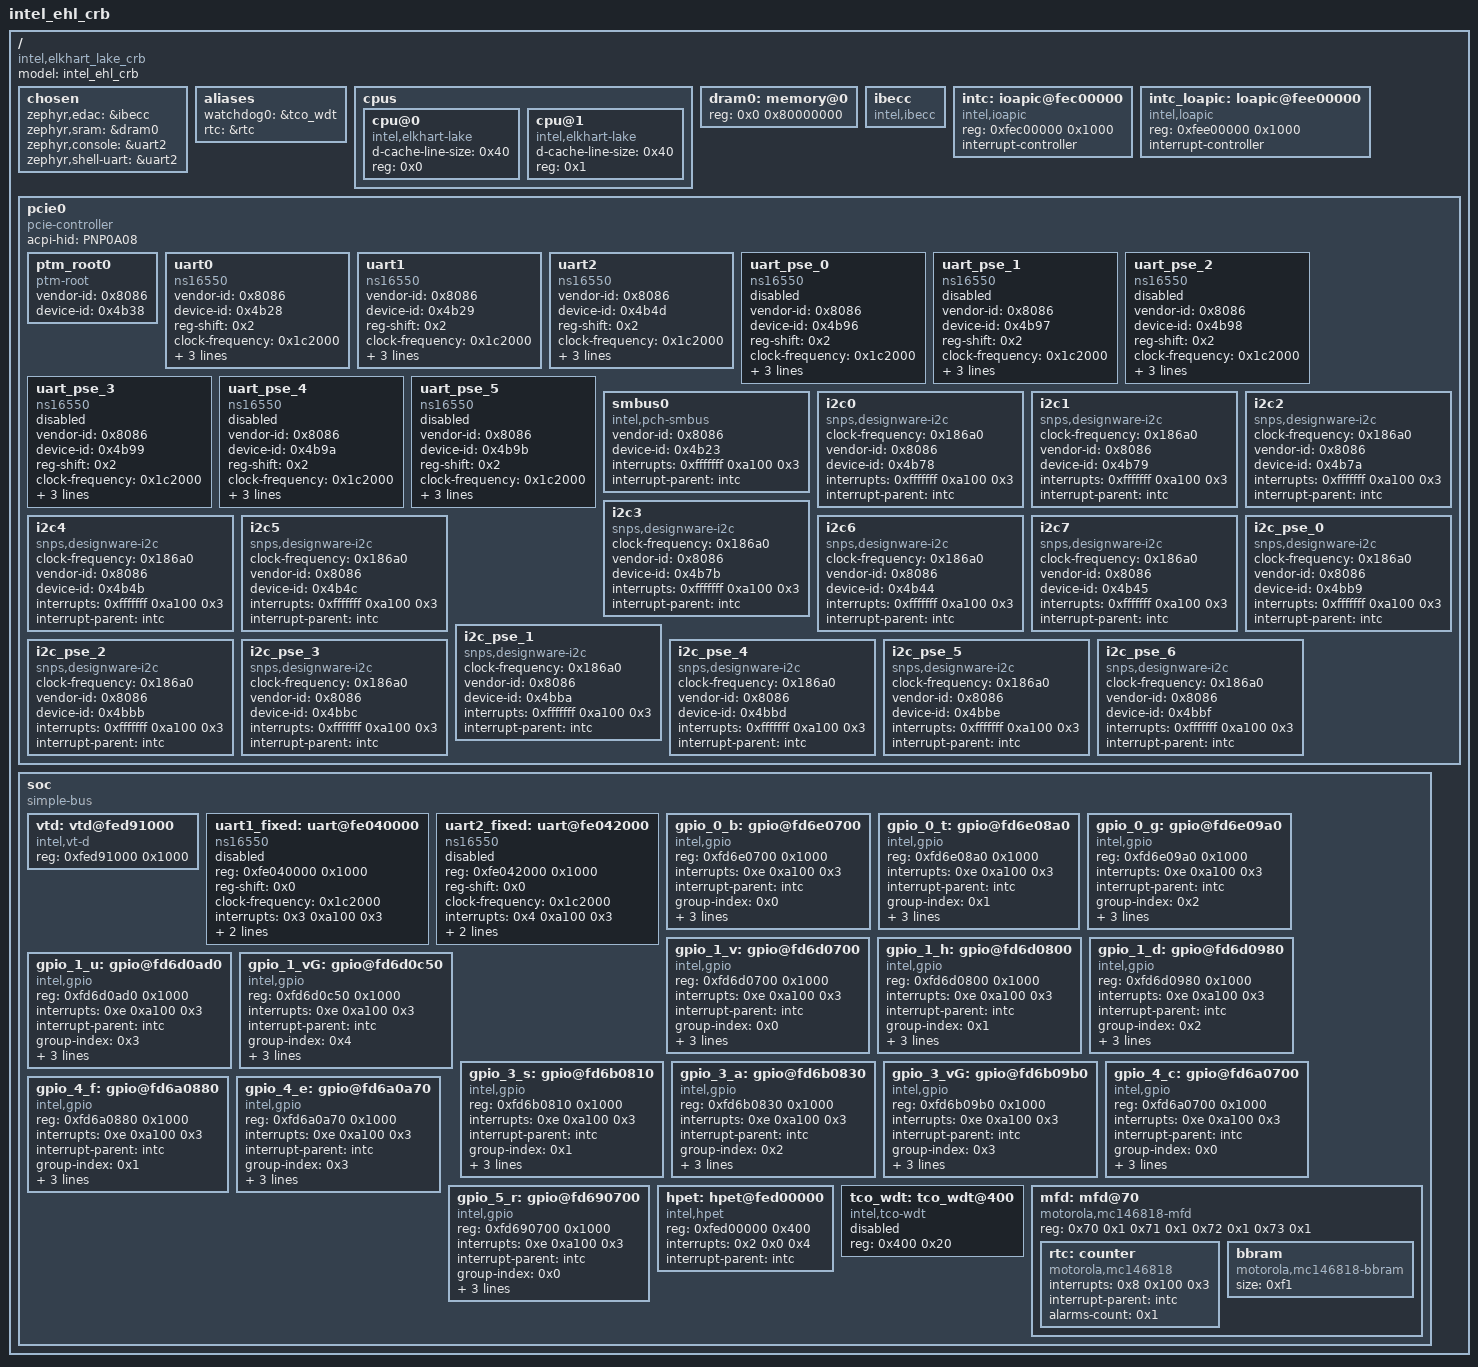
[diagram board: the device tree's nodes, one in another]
/dts-v1/;

/* node '/' defined in zephyr/dts/common/skeleton.dtsi:9 */
/ {
	#address-cells = < 0x1 >;              /* in zephyr/dts/common/skeleton.dtsi:10 */
	#size-cells = < 0x1 >;                 /* in zephyr/dts/common/skeleton.dtsi:11 */
	model = "intel_ehl_crb";               /* in zephyr/boards/intel/ehl/intel_ehl_crb.dts:16 */
	compatible = "intel,elkhart_lake_crb"; /* in zephyr/boards/intel/ehl/intel_ehl_crb.dts:17 */

	/* node '/chosen' defined in zephyr/dts/common/skeleton.dtsi:13 */
	chosen {
		zephyr,edac = &ibecc;       /* in zephyr/dts/x86/intel/elkhart_lake.dtsi:33 */
		zephyr,sram = &dram0;       /* in zephyr/boards/intel/ehl/intel_ehl_crb.dts:20 */
		zephyr,console = &uart2;    /* in zephyr/boards/intel/ehl/intel_ehl_crb.dts:21 */
		zephyr,shell-uart = &uart2; /* in zephyr/boards/intel/ehl/intel_ehl_crb.dts:22 */
	};

	/* node '/aliases' defined in zephyr/dts/common/skeleton.dtsi:15 */
	aliases {
		watchdog0 = &tco_wdt; /* in zephyr/boards/intel/ehl/intel_ehl_crb.dts:26 */
		rtc = &rtc;           /* in zephyr/boards/intel/ehl/intel_ehl_crb.dts:27 */
	};

	/* node '/cpus' defined in zephyr/dts/x86/intel/elkhart_lake.dtsi:13 */
	cpus {
		#address-cells = < 0x1 >; /* in zephyr/dts/x86/intel/elkhart_lake.dtsi:14 */
		#size-cells = < 0x0 >;    /* in zephyr/dts/x86/intel/elkhart_lake.dtsi:15 */

		/* node '/cpus/cpu@0' defined in zephyr/dts/x86/intel/elkhart_lake.dtsi:17 */
		cpu@0 {
			device_type = "cpu";               /* in zephyr/dts/x86/intel/elkhart_lake.dtsi:18 */
			compatible = "intel,elkhart-lake",
			             "intel,x86_64";       /* in zephyr/dts/x86/intel/elkhart_lake.dtsi:19 */
			d-cache-line-size = < 0x40 >;      /* in zephyr/dts/x86/intel/elkhart_lake.dtsi:20 */
			reg = < 0x0 >;                     /* in zephyr/dts/x86/intel/elkhart_lake.dtsi:21 */
		};

		/* node '/cpus/cpu@1' defined in zephyr/dts/x86/intel/elkhart_lake.dtsi:24 */
		cpu@1 {
			device_type = "cpu";               /* in zephyr/dts/x86/intel/elkhart_lake.dtsi:25 */
			compatible = "intel,elkhart-lake",
			             "intel,x86_64";       /* in zephyr/dts/x86/intel/elkhart_lake.dtsi:26 */
			d-cache-line-size = < 0x40 >;      /* in zephyr/dts/x86/intel/elkhart_lake.dtsi:27 */
			reg = < 0x1 >;                     /* in zephyr/dts/x86/intel/elkhart_lake.dtsi:28 */
		};
	};

	/* node '/memory@0' defined in zephyr/dts/x86/intel/elkhart_lake.dtsi:36 */
	dram0: memory@0 {
		device_type = "memory";   /* in zephyr/dts/x86/intel/elkhart_lake.dtsi:37 */
		reg = < 0x0 0x80000000 >; /* in zephyr/dts/x86/intel/elkhart_lake.dtsi:38 */
	};

	/* node '/ibecc' defined in zephyr/dts/x86/intel/elkhart_lake.dtsi:41 */
	ibecc: ibecc {
		compatible = "intel,ibecc"; /* in zephyr/dts/x86/intel/elkhart_lake.dtsi:42 */
		status = "okay";            /* in zephyr/dts/x86/intel/elkhart_lake.dtsi:43 */
	};

	/* node '/ioapic@fec00000' defined in zephyr/dts/x86/intel/elkhart_lake.dtsi:46 */
	intc: ioapic@fec00000 {
		compatible = "intel,ioapic"; /* in zephyr/dts/x86/intel/elkhart_lake.dtsi:47 */
		#address-cells = < 0x1 >;    /* in zephyr/dts/x86/intel/elkhart_lake.dtsi:48 */
		#interrupt-cells = < 0x3 >;  /* in zephyr/dts/x86/intel/elkhart_lake.dtsi:49 */
		reg = < 0xfec00000 0x1000 >; /* in zephyr/dts/x86/intel/elkhart_lake.dtsi:50 */
		interrupt-controller;        /* in zephyr/dts/x86/intel/elkhart_lake.dtsi:51 */
		phandle = < 0x1 >;           /* in zephyr/dts/x86/intel/elkhart_lake.dtsi:87 */
	};

	/* node '/loapic@fee00000' defined in zephyr/dts/x86/intel/elkhart_lake.dtsi:54 */
	intc_loapic: loapic@fee00000 {
		compatible = "intel,loapic"; /* in zephyr/dts/x86/intel/elkhart_lake.dtsi:55 */
		reg = < 0xfee00000 0x1000 >; /* in zephyr/dts/x86/intel/elkhart_lake.dtsi:56 */
		interrupt-controller;        /* in zephyr/dts/x86/intel/elkhart_lake.dtsi:57 */
		#interrupt-cells = < 0x3 >;  /* in zephyr/dts/x86/intel/elkhart_lake.dtsi:58 */
		#address-cells = < 0x1 >;    /* in zephyr/dts/x86/intel/elkhart_lake.dtsi:59 */
	};

	/* node '/pcie0' defined in zephyr/dts/x86/intel/elkhart_lake.dtsi:62 */
	pcie0: pcie0 {
		#address-cells = < 0x1 >;       /* in zephyr/dts/x86/intel/elkhart_lake.dtsi:63 */
		#size-cells = < 0x1 >;          /* in zephyr/dts/x86/intel/elkhart_lake.dtsi:64 */
		compatible = "pcie-controller"; /* in zephyr/dts/x86/intel/elkhart_lake.dtsi:65 */
		acpi-hid = "PNP0A08";           /* in zephyr/dts/x86/intel/elkhart_lake.dtsi:66 */
		ranges;                         /* in zephyr/dts/x86/intel/elkhart_lake.dtsi:67 */

		/* node '/pcie0/ptm_root0' defined in zephyr/dts/x86/intel/elkhart_lake.dtsi:69 */
		ptm_root0: ptm_root0 {
			compatible = "ptm-root"; /* in zephyr/dts/x86/intel/elkhart_lake.dtsi:70 */
			vendor-id = < 0x8086 >;  /* in zephyr/dts/x86/intel/elkhart_lake.dtsi:72 */
			device-id = < 0x4b38 >;  /* in zephyr/dts/x86/intel/elkhart_lake.dtsi:73 */
			status = "okay";         /* in zephyr/dts/x86/intel/elkhart_lake.dtsi:75 */
		};

		/* node '/pcie0/uart0' defined in zephyr/dts/x86/intel/elkhart_lake.dtsi:78 */
		uart0: uart0 {
			compatible = "ns16550";                /* in zephyr/dts/x86/intel/elkhart_lake.dtsi:79 */
			vendor-id = < 0x8086 >;                /* in zephyr/dts/x86/intel/elkhart_lake.dtsi:81 */
			device-id = < 0x4b28 >;                /* in zephyr/dts/x86/intel/elkhart_lake.dtsi:82 */
			reg-shift = < 0x2 >;                   /* in zephyr/dts/x86/intel/elkhart_lake.dtsi:84 */
			clock-frequency = < 0x1c2000 >;        /* in zephyr/dts/x86/intel/elkhart_lake.dtsi:85 */
			interrupts = < 0xfffffff 0xa100 0x3 >; /* in zephyr/dts/x86/intel/elkhart_lake.dtsi:86 */
			interrupt-parent = < &intc >;          /* in zephyr/dts/x86/intel/elkhart_lake.dtsi:87 */
			status = "okay";                       /* in zephyr/dts/x86/intel/elkhart_lake.dtsi:88 */
			current-speed = < 0x1c200 >;           /* in zephyr/dts/x86/intel/elkhart_lake.dtsi:89 */
		};

		/* node '/pcie0/uart1' defined in zephyr/dts/x86/intel/elkhart_lake.dtsi:92 */
		uart1: uart1 {
			compatible = "ns16550";                /* in zephyr/dts/x86/intel/elkhart_lake.dtsi:93 */
			vendor-id = < 0x8086 >;                /* in zephyr/dts/x86/intel/elkhart_lake.dtsi:95 */
			device-id = < 0x4b29 >;                /* in zephyr/dts/x86/intel/elkhart_lake.dtsi:96 */
			reg-shift = < 0x2 >;                   /* in zephyr/dts/x86/intel/elkhart_lake.dtsi:98 */
			clock-frequency = < 0x1c2000 >;        /* in zephyr/dts/x86/intel/elkhart_lake.dtsi:99 */
			interrupts = < 0xfffffff 0xa100 0x3 >; /* in zephyr/dts/x86/intel/elkhart_lake.dtsi:100 */
			interrupt-parent = < &intc >;          /* in zephyr/dts/x86/intel/elkhart_lake.dtsi:101 */
			status = "okay";                       /* in zephyr/dts/x86/intel/elkhart_lake.dtsi:103 */
			current-speed = < 0x1c200 >;           /* in zephyr/dts/x86/intel/elkhart_lake.dtsi:104 */
		};

		/* node '/pcie0/uart2' defined in zephyr/dts/x86/intel/elkhart_lake.dtsi:107 */
		uart2: uart2 {
			compatible = "ns16550";                /* in zephyr/dts/x86/intel/elkhart_lake.dtsi:108 */
			vendor-id = < 0x8086 >;                /* in zephyr/dts/x86/intel/elkhart_lake.dtsi:110 */
			device-id = < 0x4b4d >;                /* in zephyr/dts/x86/intel/elkhart_lake.dtsi:111 */
			reg-shift = < 0x2 >;                   /* in zephyr/dts/x86/intel/elkhart_lake.dtsi:113 */
			clock-frequency = < 0x1c2000 >;        /* in zephyr/dts/x86/intel/elkhart_lake.dtsi:114 */
			interrupts = < 0xfffffff 0xa100 0x3 >; /* in zephyr/dts/x86/intel/elkhart_lake.dtsi:115 */
			interrupt-parent = < &intc >;          /* in zephyr/dts/x86/intel/elkhart_lake.dtsi:116 */
			status = "okay";                       /* in zephyr/dts/x86/intel/elkhart_lake.dtsi:118 */
			current-speed = < 0x1c200 >;           /* in zephyr/dts/x86/intel/elkhart_lake.dtsi:119 */
		};

		/* node '/pcie0/uart_pse_0' defined in zephyr/dts/x86/intel/elkhart_lake.dtsi:122 */
		uart_pse_0: uart_pse_0 {
			compatible = "ns16550";                /* in zephyr/dts/x86/intel/elkhart_lake.dtsi:123 */
			vendor-id = < 0x8086 >;                /* in zephyr/dts/x86/intel/elkhart_lake.dtsi:125 */
			device-id = < 0x4b96 >;                /* in zephyr/dts/x86/intel/elkhart_lake.dtsi:126 */
			reg-shift = < 0x2 >;                   /* in zephyr/dts/x86/intel/elkhart_lake.dtsi:128 */
			clock-frequency = < 0x1c2000 >;        /* in zephyr/dts/x86/intel/elkhart_lake.dtsi:129 */
			interrupts = < 0xfffffff 0xa100 0x3 >; /* in zephyr/dts/x86/intel/elkhart_lake.dtsi:130 */
			interrupt-parent = < &intc >;          /* in zephyr/dts/x86/intel/elkhart_lake.dtsi:131 */
			status = "disabled";                   /* in zephyr/dts/x86/intel/elkhart_lake.dtsi:133 */
			current-speed = < 0x1c200 >;           /* in zephyr/dts/x86/intel/elkhart_lake.dtsi:134 */
		};

		/* node '/pcie0/uart_pse_1' defined in zephyr/dts/x86/intel/elkhart_lake.dtsi:137 */
		uart_pse_1: uart_pse_1 {
			compatible = "ns16550";                /* in zephyr/dts/x86/intel/elkhart_lake.dtsi:138 */
			vendor-id = < 0x8086 >;                /* in zephyr/dts/x86/intel/elkhart_lake.dtsi:140 */
			device-id = < 0x4b97 >;                /* in zephyr/dts/x86/intel/elkhart_lake.dtsi:141 */
			reg-shift = < 0x2 >;                   /* in zephyr/dts/x86/intel/elkhart_lake.dtsi:143 */
			clock-frequency = < 0x1c2000 >;        /* in zephyr/dts/x86/intel/elkhart_lake.dtsi:144 */
			interrupts = < 0xfffffff 0xa100 0x3 >; /* in zephyr/dts/x86/intel/elkhart_lake.dtsi:145 */
			interrupt-parent = < &intc >;          /* in zephyr/dts/x86/intel/elkhart_lake.dtsi:146 */
			status = "disabled";                   /* in zephyr/dts/x86/intel/elkhart_lake.dtsi:148 */
			current-speed = < 0x1c200 >;           /* in zephyr/dts/x86/intel/elkhart_lake.dtsi:149 */
		};

		/* node '/pcie0/uart_pse_2' defined in zephyr/dts/x86/intel/elkhart_lake.dtsi:152 */
		uart_pse_2: uart_pse_2 {
			compatible = "ns16550";                /* in zephyr/dts/x86/intel/elkhart_lake.dtsi:153 */
			vendor-id = < 0x8086 >;                /* in zephyr/dts/x86/intel/elkhart_lake.dtsi:155 */
			device-id = < 0x4b98 >;                /* in zephyr/dts/x86/intel/elkhart_lake.dtsi:156 */
			reg-shift = < 0x2 >;                   /* in zephyr/dts/x86/intel/elkhart_lake.dtsi:158 */
			clock-frequency = < 0x1c2000 >;        /* in zephyr/dts/x86/intel/elkhart_lake.dtsi:159 */
			interrupts = < 0xfffffff 0xa100 0x3 >; /* in zephyr/dts/x86/intel/elkhart_lake.dtsi:160 */
			interrupt-parent = < &intc >;          /* in zephyr/dts/x86/intel/elkhart_lake.dtsi:161 */
			status = "disabled";                   /* in zephyr/dts/x86/intel/elkhart_lake.dtsi:163 */
			current-speed = < 0x1c200 >;           /* in zephyr/dts/x86/intel/elkhart_lake.dtsi:164 */
		};

		/* node '/pcie0/uart_pse_3' defined in zephyr/dts/x86/intel/elkhart_lake.dtsi:167 */
		uart_pse_3: uart_pse_3 {
			compatible = "ns16550";                /* in zephyr/dts/x86/intel/elkhart_lake.dtsi:168 */
			vendor-id = < 0x8086 >;                /* in zephyr/dts/x86/intel/elkhart_lake.dtsi:170 */
			device-id = < 0x4b99 >;                /* in zephyr/dts/x86/intel/elkhart_lake.dtsi:171 */
			reg-shift = < 0x2 >;                   /* in zephyr/dts/x86/intel/elkhart_lake.dtsi:173 */
			clock-frequency = < 0x1c2000 >;        /* in zephyr/dts/x86/intel/elkhart_lake.dtsi:174 */
			interrupts = < 0xfffffff 0xa100 0x3 >; /* in zephyr/dts/x86/intel/elkhart_lake.dtsi:175 */
			interrupt-parent = < &intc >;          /* in zephyr/dts/x86/intel/elkhart_lake.dtsi:176 */
			status = "disabled";                   /* in zephyr/dts/x86/intel/elkhart_lake.dtsi:178 */
			current-speed = < 0x1c200 >;           /* in zephyr/dts/x86/intel/elkhart_lake.dtsi:179 */
		};

		/* node '/pcie0/uart_pse_4' defined in zephyr/dts/x86/intel/elkhart_lake.dtsi:182 */
		uart_pse_4: uart_pse_4 {
			compatible = "ns16550";                /* in zephyr/dts/x86/intel/elkhart_lake.dtsi:183 */
			vendor-id = < 0x8086 >;                /* in zephyr/dts/x86/intel/elkhart_lake.dtsi:185 */
			device-id = < 0x4b9a >;                /* in zephyr/dts/x86/intel/elkhart_lake.dtsi:186 */
			reg-shift = < 0x2 >;                   /* in zephyr/dts/x86/intel/elkhart_lake.dtsi:188 */
			clock-frequency = < 0x1c2000 >;        /* in zephyr/dts/x86/intel/elkhart_lake.dtsi:189 */
			interrupts = < 0xfffffff 0xa100 0x3 >; /* in zephyr/dts/x86/intel/elkhart_lake.dtsi:190 */
			interrupt-parent = < &intc >;          /* in zephyr/dts/x86/intel/elkhart_lake.dtsi:191 */
			status = "disabled";                   /* in zephyr/dts/x86/intel/elkhart_lake.dtsi:193 */
			current-speed = < 0x1c200 >;           /* in zephyr/dts/x86/intel/elkhart_lake.dtsi:194 */
		};

		/* node '/pcie0/uart_pse_5' defined in zephyr/dts/x86/intel/elkhart_lake.dtsi:197 */
		uart_pse_5: uart_pse_5 {
			compatible = "ns16550";                /* in zephyr/dts/x86/intel/elkhart_lake.dtsi:198 */
			vendor-id = < 0x8086 >;                /* in zephyr/dts/x86/intel/elkhart_lake.dtsi:200 */
			device-id = < 0x4b9b >;                /* in zephyr/dts/x86/intel/elkhart_lake.dtsi:201 */
			reg-shift = < 0x2 >;                   /* in zephyr/dts/x86/intel/elkhart_lake.dtsi:203 */
			clock-frequency = < 0x1c2000 >;        /* in zephyr/dts/x86/intel/elkhart_lake.dtsi:204 */
			interrupts = < 0xfffffff 0xa100 0x3 >; /* in zephyr/dts/x86/intel/elkhart_lake.dtsi:205 */
			interrupt-parent = < &intc >;          /* in zephyr/dts/x86/intel/elkhart_lake.dtsi:206 */
			status = "disabled";                   /* in zephyr/dts/x86/intel/elkhart_lake.dtsi:208 */
			current-speed = < 0x1c200 >;           /* in zephyr/dts/x86/intel/elkhart_lake.dtsi:209 */
		};

		/* node '/pcie0/smbus0' defined in zephyr/dts/x86/intel/elkhart_lake.dtsi:212 */
		smbus0: smbus0 {
			compatible = "intel,pch-smbus";        /* in zephyr/dts/x86/intel/elkhart_lake.dtsi:213 */
			#address-cells = < 0x1 >;              /* in zephyr/dts/x86/intel/elkhart_lake.dtsi:214 */
			#size-cells = < 0x0 >;                 /* in zephyr/dts/x86/intel/elkhart_lake.dtsi:215 */
			vendor-id = < 0x8086 >;                /* in zephyr/dts/x86/intel/elkhart_lake.dtsi:216 */
			device-id = < 0x4b23 >;                /* in zephyr/dts/x86/intel/elkhart_lake.dtsi:217 */
			interrupts = < 0xfffffff 0xa100 0x3 >; /* in zephyr/dts/x86/intel/elkhart_lake.dtsi:218 */
			interrupt-parent = < &intc >;          /* in zephyr/dts/x86/intel/elkhart_lake.dtsi:219 */
			status = "okay";                       /* in zephyr/dts/x86/intel/elkhart_lake.dtsi:221 */
		};

		/* node '/pcie0/i2c0' defined in zephyr/dts/x86/intel/elkhart_lake.dtsi:224 */
		i2c0: i2c0 {
			compatible = "snps,designware-i2c";    /* in zephyr/dts/x86/intel/elkhart_lake.dtsi:225 */
			clock-frequency = < 0x186a0 >;         /* in zephyr/dts/x86/intel/elkhart_lake.dtsi:226 */
			#address-cells = < 0x1 >;              /* in zephyr/dts/x86/intel/elkhart_lake.dtsi:227 */
			#size-cells = < 0x0 >;                 /* in zephyr/dts/x86/intel/elkhart_lake.dtsi:228 */
			vendor-id = < 0x8086 >;                /* in zephyr/dts/x86/intel/elkhart_lake.dtsi:229 */
			device-id = < 0x4b78 >;                /* in zephyr/dts/x86/intel/elkhart_lake.dtsi:230 */
			interrupts = < 0xfffffff 0xa100 0x3 >; /* in zephyr/dts/x86/intel/elkhart_lake.dtsi:231 */
			interrupt-parent = < &intc >;          /* in zephyr/dts/x86/intel/elkhart_lake.dtsi:232 */
			status = "okay";                       /* in zephyr/dts/x86/intel/elkhart_lake.dtsi:234 */
		};

		/* node '/pcie0/i2c1' defined in zephyr/dts/x86/intel/elkhart_lake.dtsi:237 */
		i2c1: i2c1 {
			compatible = "snps,designware-i2c";    /* in zephyr/dts/x86/intel/elkhart_lake.dtsi:238 */
			clock-frequency = < 0x186a0 >;         /* in zephyr/dts/x86/intel/elkhart_lake.dtsi:239 */
			#address-cells = < 0x1 >;              /* in zephyr/dts/x86/intel/elkhart_lake.dtsi:240 */
			#size-cells = < 0x0 >;                 /* in zephyr/dts/x86/intel/elkhart_lake.dtsi:241 */
			vendor-id = < 0x8086 >;                /* in zephyr/dts/x86/intel/elkhart_lake.dtsi:242 */
			device-id = < 0x4b79 >;                /* in zephyr/dts/x86/intel/elkhart_lake.dtsi:243 */
			interrupts = < 0xfffffff 0xa100 0x3 >; /* in zephyr/dts/x86/intel/elkhart_lake.dtsi:244 */
			interrupt-parent = < &intc >;          /* in zephyr/dts/x86/intel/elkhart_lake.dtsi:245 */
			status = "okay";                       /* in zephyr/dts/x86/intel/elkhart_lake.dtsi:247 */
		};

		/* node '/pcie0/i2c2' defined in zephyr/dts/x86/intel/elkhart_lake.dtsi:250 */
		i2c2: i2c2 {
			compatible = "snps,designware-i2c";    /* in zephyr/dts/x86/intel/elkhart_lake.dtsi:251 */
			clock-frequency = < 0x186a0 >;         /* in zephyr/dts/x86/intel/elkhart_lake.dtsi:252 */
			#address-cells = < 0x1 >;              /* in zephyr/dts/x86/intel/elkhart_lake.dtsi:253 */
			#size-cells = < 0x0 >;                 /* in zephyr/dts/x86/intel/elkhart_lake.dtsi:254 */
			vendor-id = < 0x8086 >;                /* in zephyr/dts/x86/intel/elkhart_lake.dtsi:255 */
			device-id = < 0x4b7a >;                /* in zephyr/dts/x86/intel/elkhart_lake.dtsi:256 */
			interrupts = < 0xfffffff 0xa100 0x3 >; /* in zephyr/dts/x86/intel/elkhart_lake.dtsi:257 */
			interrupt-parent = < &intc >;          /* in zephyr/dts/x86/intel/elkhart_lake.dtsi:258 */
			status = "okay";                       /* in zephyr/dts/x86/intel/elkhart_lake.dtsi:260 */
		};

		/* node '/pcie0/i2c3' defined in zephyr/dts/x86/intel/elkhart_lake.dtsi:263 */
		i2c3: i2c3 {
			compatible = "snps,designware-i2c";    /* in zephyr/dts/x86/intel/elkhart_lake.dtsi:264 */
			clock-frequency = < 0x186a0 >;         /* in zephyr/dts/x86/intel/elkhart_lake.dtsi:265 */
			#address-cells = < 0x1 >;              /* in zephyr/dts/x86/intel/elkhart_lake.dtsi:266 */
			#size-cells = < 0x0 >;                 /* in zephyr/dts/x86/intel/elkhart_lake.dtsi:267 */
			vendor-id = < 0x8086 >;                /* in zephyr/dts/x86/intel/elkhart_lake.dtsi:268 */
			device-id = < 0x4b7b >;                /* in zephyr/dts/x86/intel/elkhart_lake.dtsi:269 */
			interrupts = < 0xfffffff 0xa100 0x3 >; /* in zephyr/dts/x86/intel/elkhart_lake.dtsi:270 */
			interrupt-parent = < &intc >;          /* in zephyr/dts/x86/intel/elkhart_lake.dtsi:271 */
			status = "okay";                       /* in zephyr/dts/x86/intel/elkhart_lake.dtsi:273 */
		};

		/* node '/pcie0/i2c4' defined in zephyr/dts/x86/intel/elkhart_lake.dtsi:276 */
		i2c4: i2c4 {
			compatible = "snps,designware-i2c";    /* in zephyr/dts/x86/intel/elkhart_lake.dtsi:277 */
			clock-frequency = < 0x186a0 >;         /* in zephyr/dts/x86/intel/elkhart_lake.dtsi:278 */
			#address-cells = < 0x1 >;              /* in zephyr/dts/x86/intel/elkhart_lake.dtsi:279 */
			#size-cells = < 0x0 >;                 /* in zephyr/dts/x86/intel/elkhart_lake.dtsi:280 */
			vendor-id = < 0x8086 >;                /* in zephyr/dts/x86/intel/elkhart_lake.dtsi:281 */
			device-id = < 0x4b4b >;                /* in zephyr/dts/x86/intel/elkhart_lake.dtsi:282 */
			interrupts = < 0xfffffff 0xa100 0x3 >; /* in zephyr/dts/x86/intel/elkhart_lake.dtsi:283 */
			interrupt-parent = < &intc >;          /* in zephyr/dts/x86/intel/elkhart_lake.dtsi:284 */
			status = "okay";                       /* in zephyr/dts/x86/intel/elkhart_lake.dtsi:286 */
		};

		/* node '/pcie0/i2c5' defined in zephyr/dts/x86/intel/elkhart_lake.dtsi:289 */
		i2c5: i2c5 {
			compatible = "snps,designware-i2c";    /* in zephyr/dts/x86/intel/elkhart_lake.dtsi:290 */
			clock-frequency = < 0x186a0 >;         /* in zephyr/dts/x86/intel/elkhart_lake.dtsi:291 */
			#address-cells = < 0x1 >;              /* in zephyr/dts/x86/intel/elkhart_lake.dtsi:292 */
			#size-cells = < 0x0 >;                 /* in zephyr/dts/x86/intel/elkhart_lake.dtsi:293 */
			vendor-id = < 0x8086 >;                /* in zephyr/dts/x86/intel/elkhart_lake.dtsi:294 */
			device-id = < 0x4b4c >;                /* in zephyr/dts/x86/intel/elkhart_lake.dtsi:295 */
			interrupts = < 0xfffffff 0xa100 0x3 >; /* in zephyr/dts/x86/intel/elkhart_lake.dtsi:296 */
			interrupt-parent = < &intc >;          /* in zephyr/dts/x86/intel/elkhart_lake.dtsi:297 */
			status = "okay";                       /* in zephyr/dts/x86/intel/elkhart_lake.dtsi:299 */
		};

		/* node '/pcie0/i2c6' defined in zephyr/dts/x86/intel/elkhart_lake.dtsi:302 */
		i2c6: i2c6 {
			compatible = "snps,designware-i2c";    /* in zephyr/dts/x86/intel/elkhart_lake.dtsi:303 */
			clock-frequency = < 0x186a0 >;         /* in zephyr/dts/x86/intel/elkhart_lake.dtsi:304 */
			#address-cells = < 0x1 >;              /* in zephyr/dts/x86/intel/elkhart_lake.dtsi:305 */
			#size-cells = < 0x0 >;                 /* in zephyr/dts/x86/intel/elkhart_lake.dtsi:306 */
			vendor-id = < 0x8086 >;                /* in zephyr/dts/x86/intel/elkhart_lake.dtsi:307 */
			device-id = < 0x4b44 >;                /* in zephyr/dts/x86/intel/elkhart_lake.dtsi:308 */
			interrupts = < 0xfffffff 0xa100 0x3 >; /* in zephyr/dts/x86/intel/elkhart_lake.dtsi:309 */
			interrupt-parent = < &intc >;          /* in zephyr/dts/x86/intel/elkhart_lake.dtsi:310 */
			status = "okay";                       /* in zephyr/dts/x86/intel/elkhart_lake.dtsi:312 */
		};

		/* node '/pcie0/i2c7' defined in zephyr/dts/x86/intel/elkhart_lake.dtsi:315 */
		i2c7: i2c7 {
			compatible = "snps,designware-i2c";    /* in zephyr/dts/x86/intel/elkhart_lake.dtsi:316 */
			clock-frequency = < 0x186a0 >;         /* in zephyr/dts/x86/intel/elkhart_lake.dtsi:317 */
			#address-cells = < 0x1 >;              /* in zephyr/dts/x86/intel/elkhart_lake.dtsi:318 */
			#size-cells = < 0x0 >;                 /* in zephyr/dts/x86/intel/elkhart_lake.dtsi:319 */
			vendor-id = < 0x8086 >;                /* in zephyr/dts/x86/intel/elkhart_lake.dtsi:320 */
			device-id = < 0x4b45 >;                /* in zephyr/dts/x86/intel/elkhart_lake.dtsi:321 */
			interrupts = < 0xfffffff 0xa100 0x3 >; /* in zephyr/dts/x86/intel/elkhart_lake.dtsi:322 */
			interrupt-parent = < &intc >;          /* in zephyr/dts/x86/intel/elkhart_lake.dtsi:323 */
			status = "okay";                       /* in zephyr/dts/x86/intel/elkhart_lake.dtsi:325 */
		};

		/* node '/pcie0/i2c_pse_0' defined in zephyr/dts/x86/intel/elkhart_lake.dtsi:328 */
		i2c_pse_0: i2c_pse_0 {
			compatible = "snps,designware-i2c";    /* in zephyr/dts/x86/intel/elkhart_lake.dtsi:329 */
			clock-frequency = < 0x186a0 >;         /* in zephyr/dts/x86/intel/elkhart_lake.dtsi:330 */
			#address-cells = < 0x1 >;              /* in zephyr/dts/x86/intel/elkhart_lake.dtsi:331 */
			#size-cells = < 0x0 >;                 /* in zephyr/dts/x86/intel/elkhart_lake.dtsi:332 */
			vendor-id = < 0x8086 >;                /* in zephyr/dts/x86/intel/elkhart_lake.dtsi:333 */
			device-id = < 0x4bb9 >;                /* in zephyr/dts/x86/intel/elkhart_lake.dtsi:334 */
			interrupts = < 0xfffffff 0xa100 0x3 >; /* in zephyr/dts/x86/intel/elkhart_lake.dtsi:335 */
			interrupt-parent = < &intc >;          /* in zephyr/dts/x86/intel/elkhart_lake.dtsi:336 */
			status = "okay";                       /* in zephyr/dts/x86/intel/elkhart_lake.dtsi:338 */
		};

		/* node '/pcie0/i2c_pse_1' defined in zephyr/dts/x86/intel/elkhart_lake.dtsi:341 */
		i2c_pse_1: i2c_pse_1 {
			compatible = "snps,designware-i2c";    /* in zephyr/dts/x86/intel/elkhart_lake.dtsi:342 */
			clock-frequency = < 0x186a0 >;         /* in zephyr/dts/x86/intel/elkhart_lake.dtsi:343 */
			#address-cells = < 0x1 >;              /* in zephyr/dts/x86/intel/elkhart_lake.dtsi:344 */
			#size-cells = < 0x0 >;                 /* in zephyr/dts/x86/intel/elkhart_lake.dtsi:345 */
			vendor-id = < 0x8086 >;                /* in zephyr/dts/x86/intel/elkhart_lake.dtsi:346 */
			device-id = < 0x4bba >;                /* in zephyr/dts/x86/intel/elkhart_lake.dtsi:347 */
			interrupts = < 0xfffffff 0xa100 0x3 >; /* in zephyr/dts/x86/intel/elkhart_lake.dtsi:348 */
			interrupt-parent = < &intc >;          /* in zephyr/dts/x86/intel/elkhart_lake.dtsi:349 */
			status = "okay";                       /* in zephyr/dts/x86/intel/elkhart_lake.dtsi:351 */
		};

		/* node '/pcie0/i2c_pse_2' defined in zephyr/dts/x86/intel/elkhart_lake.dtsi:354 */
		i2c_pse_2: i2c_pse_2 {
			compatible = "snps,designware-i2c";    /* in zephyr/dts/x86/intel/elkhart_lake.dtsi:355 */
			clock-frequency = < 0x186a0 >;         /* in zephyr/dts/x86/intel/elkhart_lake.dtsi:356 */
			#address-cells = < 0x1 >;              /* in zephyr/dts/x86/intel/elkhart_lake.dtsi:357 */
			#size-cells = < 0x0 >;                 /* in zephyr/dts/x86/intel/elkhart_lake.dtsi:358 */
			vendor-id = < 0x8086 >;                /* in zephyr/dts/x86/intel/elkhart_lake.dtsi:359 */
			device-id = < 0x4bbb >;                /* in zephyr/dts/x86/intel/elkhart_lake.dtsi:360 */
			interrupts = < 0xfffffff 0xa100 0x3 >; /* in zephyr/dts/x86/intel/elkhart_lake.dtsi:361 */
			interrupt-parent = < &intc >;          /* in zephyr/dts/x86/intel/elkhart_lake.dtsi:362 */
			status = "okay";                       /* in zephyr/dts/x86/intel/elkhart_lake.dtsi:364 */
		};

		/* node '/pcie0/i2c_pse_3' defined in zephyr/dts/x86/intel/elkhart_lake.dtsi:367 */
		i2c_pse_3: i2c_pse_3 {
			compatible = "snps,designware-i2c";    /* in zephyr/dts/x86/intel/elkhart_lake.dtsi:368 */
			clock-frequency = < 0x186a0 >;         /* in zephyr/dts/x86/intel/elkhart_lake.dtsi:369 */
			#address-cells = < 0x1 >;              /* in zephyr/dts/x86/intel/elkhart_lake.dtsi:370 */
			#size-cells = < 0x0 >;                 /* in zephyr/dts/x86/intel/elkhart_lake.dtsi:371 */
			vendor-id = < 0x8086 >;                /* in zephyr/dts/x86/intel/elkhart_lake.dtsi:372 */
			device-id = < 0x4bbc >;                /* in zephyr/dts/x86/intel/elkhart_lake.dtsi:373 */
			interrupts = < 0xfffffff 0xa100 0x3 >; /* in zephyr/dts/x86/intel/elkhart_lake.dtsi:374 */
			interrupt-parent = < &intc >;          /* in zephyr/dts/x86/intel/elkhart_lake.dtsi:375 */
			status = "okay";                       /* in zephyr/dts/x86/intel/elkhart_lake.dtsi:377 */
		};

		/* node '/pcie0/i2c_pse_4' defined in zephyr/dts/x86/intel/elkhart_lake.dtsi:380 */
		i2c_pse_4: i2c_pse_4 {
			compatible = "snps,designware-i2c";    /* in zephyr/dts/x86/intel/elkhart_lake.dtsi:381 */
			clock-frequency = < 0x186a0 >;         /* in zephyr/dts/x86/intel/elkhart_lake.dtsi:382 */
			#address-cells = < 0x1 >;              /* in zephyr/dts/x86/intel/elkhart_lake.dtsi:383 */
			#size-cells = < 0x0 >;                 /* in zephyr/dts/x86/intel/elkhart_lake.dtsi:384 */
			vendor-id = < 0x8086 >;                /* in zephyr/dts/x86/intel/elkhart_lake.dtsi:385 */
			device-id = < 0x4bbd >;                /* in zephyr/dts/x86/intel/elkhart_lake.dtsi:386 */
			interrupts = < 0xfffffff 0xa100 0x3 >; /* in zephyr/dts/x86/intel/elkhart_lake.dtsi:387 */
			interrupt-parent = < &intc >;          /* in zephyr/dts/x86/intel/elkhart_lake.dtsi:388 */
			status = "okay";                       /* in zephyr/dts/x86/intel/elkhart_lake.dtsi:390 */
		};

		/* node '/pcie0/i2c_pse_5' defined in zephyr/dts/x86/intel/elkhart_lake.dtsi:393 */
		i2c_pse_5: i2c_pse_5 {
			compatible = "snps,designware-i2c";    /* in zephyr/dts/x86/intel/elkhart_lake.dtsi:394 */
			clock-frequency = < 0x186a0 >;         /* in zephyr/dts/x86/intel/elkhart_lake.dtsi:395 */
			#address-cells = < 0x1 >;              /* in zephyr/dts/x86/intel/elkhart_lake.dtsi:396 */
			#size-cells = < 0x0 >;                 /* in zephyr/dts/x86/intel/elkhart_lake.dtsi:397 */
			vendor-id = < 0x8086 >;                /* in zephyr/dts/x86/intel/elkhart_lake.dtsi:398 */
			device-id = < 0x4bbe >;                /* in zephyr/dts/x86/intel/elkhart_lake.dtsi:399 */
			interrupts = < 0xfffffff 0xa100 0x3 >; /* in zephyr/dts/x86/intel/elkhart_lake.dtsi:400 */
			interrupt-parent = < &intc >;          /* in zephyr/dts/x86/intel/elkhart_lake.dtsi:401 */
			status = "okay";                       /* in zephyr/dts/x86/intel/elkhart_lake.dtsi:403 */
		};

		/* node '/pcie0/i2c_pse_6' defined in zephyr/dts/x86/intel/elkhart_lake.dtsi:406 */
		i2c_pse_6: i2c_pse_6 {
			compatible = "snps,designware-i2c";    /* in zephyr/dts/x86/intel/elkhart_lake.dtsi:407 */
			clock-frequency = < 0x186a0 >;         /* in zephyr/dts/x86/intel/elkhart_lake.dtsi:408 */
			#address-cells = < 0x1 >;              /* in zephyr/dts/x86/intel/elkhart_lake.dtsi:409 */
			#size-cells = < 0x0 >;                 /* in zephyr/dts/x86/intel/elkhart_lake.dtsi:410 */
			vendor-id = < 0x8086 >;                /* in zephyr/dts/x86/intel/elkhart_lake.dtsi:411 */
			device-id = < 0x4bbf >;                /* in zephyr/dts/x86/intel/elkhart_lake.dtsi:412 */
			interrupts = < 0xfffffff 0xa100 0x3 >; /* in zephyr/dts/x86/intel/elkhart_lake.dtsi:413 */
			interrupt-parent = < &intc >;          /* in zephyr/dts/x86/intel/elkhart_lake.dtsi:414 */
			status = "okay";                       /* in zephyr/dts/x86/intel/elkhart_lake.dtsi:416 */
		};
	};

	/* node '/soc' defined in zephyr/dts/x86/intel/elkhart_lake.dtsi:420 */
	soc {
		#address-cells = < 0x1 >;  /* in zephyr/dts/x86/intel/elkhart_lake.dtsi:421 */
		#size-cells = < 0x1 >;     /* in zephyr/dts/x86/intel/elkhart_lake.dtsi:422 */
		compatible = "simple-bus"; /* in zephyr/dts/x86/intel/elkhart_lake.dtsi:423 */
		ranges;                    /* in zephyr/dts/x86/intel/elkhart_lake.dtsi:424 */

		/* node '/soc/vtd@fed91000' defined in zephyr/dts/x86/intel/elkhart_lake.dtsi:426 */
		vtd: vtd@fed91000 {
			compatible = "intel,vt-d";   /* in zephyr/dts/x86/intel/elkhart_lake.dtsi:427 */
			reg = < 0xfed91000 0x1000 >; /* in zephyr/dts/x86/intel/elkhart_lake.dtsi:429 */
			status = "okay";             /* in zephyr/dts/x86/intel/elkhart_lake.dtsi:431 */
		};

		/* node '/soc/uart@fe040000' defined in zephyr/dts/x86/intel/elkhart_lake.dtsi:434 */
		uart1_fixed: uart@fe040000 {
			compatible = "ns16550";          /* in zephyr/dts/x86/intel/elkhart_lake.dtsi:435 */
			reg = < 0xfe040000 0x1000 >;     /* in zephyr/dts/x86/intel/elkhart_lake.dtsi:437 */
			reg-shift = < 0x0 >;             /* in zephyr/dts/x86/intel/elkhart_lake.dtsi:438 */
			clock-frequency = < 0x1c2000 >;  /* in zephyr/dts/x86/intel/elkhart_lake.dtsi:440 */
			interrupts = < 0x3 0xa100 0x3 >; /* in zephyr/dts/x86/intel/elkhart_lake.dtsi:441 */
			interrupt-parent = < &intc >;    /* in zephyr/dts/x86/intel/elkhart_lake.dtsi:442 */
			status = "disabled";             /* in zephyr/dts/x86/intel/elkhart_lake.dtsi:444 */
			current-speed = < 0x1c200 >;     /* in zephyr/dts/x86/intel/elkhart_lake.dtsi:445 */
		};

		/* node '/soc/uart@fe042000' defined in zephyr/dts/x86/intel/elkhart_lake.dtsi:448 */
		uart2_fixed: uart@fe042000 {
			compatible = "ns16550";          /* in zephyr/dts/x86/intel/elkhart_lake.dtsi:449 */
			reg = < 0xfe042000 0x1000 >;     /* in zephyr/dts/x86/intel/elkhart_lake.dtsi:451 */
			reg-shift = < 0x0 >;             /* in zephyr/dts/x86/intel/elkhart_lake.dtsi:452 */
			clock-frequency = < 0x1c2000 >;  /* in zephyr/dts/x86/intel/elkhart_lake.dtsi:454 */
			interrupts = < 0x4 0xa100 0x3 >; /* in zephyr/dts/x86/intel/elkhart_lake.dtsi:455 */
			interrupt-parent = < &intc >;    /* in zephyr/dts/x86/intel/elkhart_lake.dtsi:456 */
			status = "disabled";             /* in zephyr/dts/x86/intel/elkhart_lake.dtsi:458 */
			current-speed = < 0x1c200 >;     /* in zephyr/dts/x86/intel/elkhart_lake.dtsi:459 */
		};

		/* node '/soc/gpio@fd6e0700' defined in zephyr/dts/x86/intel/elkhart_lake.dtsi:462 */
		gpio_0_b: gpio@fd6e0700 {
			compatible = "intel,gpio";       /* in zephyr/dts/x86/intel/elkhart_lake.dtsi:463 */
			reg = < 0xfd6e0700 0x1000 >;     /* in zephyr/dts/x86/intel/elkhart_lake.dtsi:464 */
			interrupts = < 0xe 0xa100 0x3 >; /* in zephyr/dts/x86/intel/elkhart_lake.dtsi:465 */
			interrupt-parent = < &intc >;    /* in zephyr/dts/x86/intel/elkhart_lake.dtsi:466 */
			group-index = < 0x0 >;           /* in zephyr/dts/x86/intel/elkhart_lake.dtsi:468 */
			gpio-controller;                 /* in zephyr/dts/x86/intel/elkhart_lake.dtsi:469 */
			#gpio-cells = < 0x2 >;           /* in zephyr/dts/x86/intel/elkhart_lake.dtsi:470 */
			ngpios = < 0x18 >;               /* in zephyr/dts/x86/intel/elkhart_lake.dtsi:472 */
			pin-offset = < 0x0 >;            /* in zephyr/dts/x86/intel/elkhart_lake.dtsi:473 */
			status = "okay";                 /* in zephyr/dts/x86/intel/elkhart_lake.dtsi:475 */
		};

		/* node '/soc/gpio@fd6e08a0' defined in zephyr/dts/x86/intel/elkhart_lake.dtsi:478 */
		gpio_0_t: gpio@fd6e08a0 {
			compatible = "intel,gpio";       /* in zephyr/dts/x86/intel/elkhart_lake.dtsi:479 */
			reg = < 0xfd6e08a0 0x1000 >;     /* in zephyr/dts/x86/intel/elkhart_lake.dtsi:480 */
			interrupts = < 0xe 0xa100 0x3 >; /* in zephyr/dts/x86/intel/elkhart_lake.dtsi:481 */
			interrupt-parent = < &intc >;    /* in zephyr/dts/x86/intel/elkhart_lake.dtsi:482 */
			group-index = < 0x1 >;           /* in zephyr/dts/x86/intel/elkhart_lake.dtsi:484 */
			gpio-controller;                 /* in zephyr/dts/x86/intel/elkhart_lake.dtsi:485 */
			#gpio-cells = < 0x2 >;           /* in zephyr/dts/x86/intel/elkhart_lake.dtsi:486 */
			ngpios = < 0x10 >;               /* in zephyr/dts/x86/intel/elkhart_lake.dtsi:488 */
			pin-offset = < 0x1a >;           /* in zephyr/dts/x86/intel/elkhart_lake.dtsi:489 */
			status = "okay";                 /* in zephyr/dts/x86/intel/elkhart_lake.dtsi:491 */
		};

		/* node '/soc/gpio@fd6e09a0' defined in zephyr/dts/x86/intel/elkhart_lake.dtsi:494 */
		gpio_0_g: gpio@fd6e09a0 {
			compatible = "intel,gpio";       /* in zephyr/dts/x86/intel/elkhart_lake.dtsi:495 */
			reg = < 0xfd6e09a0 0x1000 >;     /* in zephyr/dts/x86/intel/elkhart_lake.dtsi:496 */
			interrupts = < 0xe 0xa100 0x3 >; /* in zephyr/dts/x86/intel/elkhart_lake.dtsi:497 */
			interrupt-parent = < &intc >;    /* in zephyr/dts/x86/intel/elkhart_lake.dtsi:498 */
			group-index = < 0x2 >;           /* in zephyr/dts/x86/intel/elkhart_lake.dtsi:500 */
			gpio-controller;                 /* in zephyr/dts/x86/intel/elkhart_lake.dtsi:501 */
			#gpio-cells = < 0x2 >;           /* in zephyr/dts/x86/intel/elkhart_lake.dtsi:502 */
			ngpios = < 0x18 >;               /* in zephyr/dts/x86/intel/elkhart_lake.dtsi:504 */
			pin-offset = < 0x2a >;           /* in zephyr/dts/x86/intel/elkhart_lake.dtsi:505 */
			status = "okay";                 /* in zephyr/dts/x86/intel/elkhart_lake.dtsi:507 */
		};

		/* node '/soc/gpio@fd6d0700' defined in zephyr/dts/x86/intel/elkhart_lake.dtsi:510 */
		gpio_1_v: gpio@fd6d0700 {
			compatible = "intel,gpio";       /* in zephyr/dts/x86/intel/elkhart_lake.dtsi:511 */
			reg = < 0xfd6d0700 0x1000 >;     /* in zephyr/dts/x86/intel/elkhart_lake.dtsi:512 */
			interrupts = < 0xe 0xa100 0x3 >; /* in zephyr/dts/x86/intel/elkhart_lake.dtsi:513 */
			interrupt-parent = < &intc >;    /* in zephyr/dts/x86/intel/elkhart_lake.dtsi:514 */
			group-index = < 0x0 >;           /* in zephyr/dts/x86/intel/elkhart_lake.dtsi:516 */
			gpio-controller;                 /* in zephyr/dts/x86/intel/elkhart_lake.dtsi:517 */
			#gpio-cells = < 0x2 >;           /* in zephyr/dts/x86/intel/elkhart_lake.dtsi:518 */
			ngpios = < 0x10 >;               /* in zephyr/dts/x86/intel/elkhart_lake.dtsi:520 */
			pin-offset = < 0x0 >;            /* in zephyr/dts/x86/intel/elkhart_lake.dtsi:521 */
			status = "okay";                 /* in zephyr/dts/x86/intel/elkhart_lake.dtsi:523 */
		};

		/* node '/soc/gpio@fd6d0800' defined in zephyr/dts/x86/intel/elkhart_lake.dtsi:526 */
		gpio_1_h: gpio@fd6d0800 {
			compatible = "intel,gpio";       /* in zephyr/dts/x86/intel/elkhart_lake.dtsi:527 */
			reg = < 0xfd6d0800 0x1000 >;     /* in zephyr/dts/x86/intel/elkhart_lake.dtsi:528 */
			interrupts = < 0xe 0xa100 0x3 >; /* in zephyr/dts/x86/intel/elkhart_lake.dtsi:529 */
			interrupt-parent = < &intc >;    /* in zephyr/dts/x86/intel/elkhart_lake.dtsi:530 */
			group-index = < 0x1 >;           /* in zephyr/dts/x86/intel/elkhart_lake.dtsi:532 */
			gpio-controller;                 /* in zephyr/dts/x86/intel/elkhart_lake.dtsi:533 */
			#gpio-cells = < 0x2 >;           /* in zephyr/dts/x86/intel/elkhart_lake.dtsi:534 */
			ngpios = < 0x18 >;               /* in zephyr/dts/x86/intel/elkhart_lake.dtsi:536 */
			pin-offset = < 0x10 >;           /* in zephyr/dts/x86/intel/elkhart_lake.dtsi:537 */
			status = "okay";                 /* in zephyr/dts/x86/intel/elkhart_lake.dtsi:539 */
		};

		/* node '/soc/gpio@fd6d0980' defined in zephyr/dts/x86/intel/elkhart_lake.dtsi:542 */
		gpio_1_d: gpio@fd6d0980 {
			compatible = "intel,gpio";       /* in zephyr/dts/x86/intel/elkhart_lake.dtsi:543 */
			reg = < 0xfd6d0980 0x1000 >;     /* in zephyr/dts/x86/intel/elkhart_lake.dtsi:544 */
			interrupts = < 0xe 0xa100 0x3 >; /* in zephyr/dts/x86/intel/elkhart_lake.dtsi:545 */
			interrupt-parent = < &intc >;    /* in zephyr/dts/x86/intel/elkhart_lake.dtsi:546 */
			group-index = < 0x2 >;           /* in zephyr/dts/x86/intel/elkhart_lake.dtsi:548 */
			gpio-controller;                 /* in zephyr/dts/x86/intel/elkhart_lake.dtsi:549 */
			#gpio-cells = < 0x2 >;           /* in zephyr/dts/x86/intel/elkhart_lake.dtsi:550 */
			ngpios = < 0x14 >;               /* in zephyr/dts/x86/intel/elkhart_lake.dtsi:552 */
			pin-offset = < 0x28 >;           /* in zephyr/dts/x86/intel/elkhart_lake.dtsi:553 */
			status = "okay";                 /* in zephyr/dts/x86/intel/elkhart_lake.dtsi:555 */
		};

		/* node '/soc/gpio@fd6d0ad0' defined in zephyr/dts/x86/intel/elkhart_lake.dtsi:558 */
		gpio_1_u: gpio@fd6d0ad0 {
			compatible = "intel,gpio";       /* in zephyr/dts/x86/intel/elkhart_lake.dtsi:559 */
			reg = < 0xfd6d0ad0 0x1000 >;     /* in zephyr/dts/x86/intel/elkhart_lake.dtsi:560 */
			interrupts = < 0xe 0xa100 0x3 >; /* in zephyr/dts/x86/intel/elkhart_lake.dtsi:561 */
			interrupt-parent = < &intc >;    /* in zephyr/dts/x86/intel/elkhart_lake.dtsi:562 */
			group-index = < 0x3 >;           /* in zephyr/dts/x86/intel/elkhart_lake.dtsi:564 */
			gpio-controller;                 /* in zephyr/dts/x86/intel/elkhart_lake.dtsi:565 */
			#gpio-cells = < 0x2 >;           /* in zephyr/dts/x86/intel/elkhart_lake.dtsi:566 */
			ngpios = < 0x14 >;               /* in zephyr/dts/x86/intel/elkhart_lake.dtsi:568 */
			pin-offset = < 0x3d >;           /* in zephyr/dts/x86/intel/elkhart_lake.dtsi:569 */
			status = "okay";                 /* in zephyr/dts/x86/intel/elkhart_lake.dtsi:571 */
		};

		/* node '/soc/gpio@fd6d0c50' defined in zephyr/dts/x86/intel/elkhart_lake.dtsi:574 */
		gpio_1_vG: gpio@fd6d0c50 {
			compatible = "intel,gpio";       /* in zephyr/dts/x86/intel/elkhart_lake.dtsi:575 */
			reg = < 0xfd6d0c50 0x1000 >;     /* in zephyr/dts/x86/intel/elkhart_lake.dtsi:576 */
			interrupts = < 0xe 0xa100 0x3 >; /* in zephyr/dts/x86/intel/elkhart_lake.dtsi:577 */
			interrupt-parent = < &intc >;    /* in zephyr/dts/x86/intel/elkhart_lake.dtsi:578 */
			group-index = < 0x4 >;           /* in zephyr/dts/x86/intel/elkhart_lake.dtsi:580 */
			gpio-controller;                 /* in zephyr/dts/x86/intel/elkhart_lake.dtsi:581 */
			#gpio-cells = < 0x2 >;           /* in zephyr/dts/x86/intel/elkhart_lake.dtsi:582 */
			ngpios = < 0x1c >;               /* in zephyr/dts/x86/intel/elkhart_lake.dtsi:584 */
			pin-offset = < 0x55 >;           /* in zephyr/dts/x86/intel/elkhart_lake.dtsi:585 */
			status = "okay";                 /* in zephyr/dts/x86/intel/elkhart_lake.dtsi:587 */
		};

		/* node '/soc/gpio@fd6b0810' defined in zephyr/dts/x86/intel/elkhart_lake.dtsi:590 */
		gpio_3_s: gpio@fd6b0810 {
			compatible = "intel,gpio";       /* in zephyr/dts/x86/intel/elkhart_lake.dtsi:591 */
			reg = < 0xfd6b0810 0x1000 >;     /* in zephyr/dts/x86/intel/elkhart_lake.dtsi:592 */
			interrupts = < 0xe 0xa100 0x3 >; /* in zephyr/dts/x86/intel/elkhart_lake.dtsi:593 */
			interrupt-parent = < &intc >;    /* in zephyr/dts/x86/intel/elkhart_lake.dtsi:594 */
			group-index = < 0x1 >;           /* in zephyr/dts/x86/intel/elkhart_lake.dtsi:596 */
			gpio-controller;                 /* in zephyr/dts/x86/intel/elkhart_lake.dtsi:597 */
			#gpio-cells = < 0x2 >;           /* in zephyr/dts/x86/intel/elkhart_lake.dtsi:598 */
			ngpios = < 0x2 >;                /* in zephyr/dts/x86/intel/elkhart_lake.dtsi:600 */
			pin-offset = < 0x11 >;           /* in zephyr/dts/x86/intel/elkhart_lake.dtsi:601 */
			status = "okay";                 /* in zephyr/dts/x86/intel/elkhart_lake.dtsi:603 */
		};

		/* node '/soc/gpio@fd6b0830' defined in zephyr/dts/x86/intel/elkhart_lake.dtsi:606 */
		gpio_3_a: gpio@fd6b0830 {
			compatible = "intel,gpio";       /* in zephyr/dts/x86/intel/elkhart_lake.dtsi:607 */
			reg = < 0xfd6b0830 0x1000 >;     /* in zephyr/dts/x86/intel/elkhart_lake.dtsi:608 */
			interrupts = < 0xe 0xa100 0x3 >; /* in zephyr/dts/x86/intel/elkhart_lake.dtsi:609 */
			interrupt-parent = < &intc >;    /* in zephyr/dts/x86/intel/elkhart_lake.dtsi:610 */
			group-index = < 0x2 >;           /* in zephyr/dts/x86/intel/elkhart_lake.dtsi:612 */
			gpio-controller;                 /* in zephyr/dts/x86/intel/elkhart_lake.dtsi:613 */
			#gpio-cells = < 0x2 >;           /* in zephyr/dts/x86/intel/elkhart_lake.dtsi:614 */
			ngpios = < 0x18 >;               /* in zephyr/dts/x86/intel/elkhart_lake.dtsi:616 */
			pin-offset = < 0x19 >;           /* in zephyr/dts/x86/intel/elkhart_lake.dtsi:617 */
			status = "okay";                 /* in zephyr/dts/x86/intel/elkhart_lake.dtsi:619 */
		};

		/* node '/soc/gpio@fd6b09b0' defined in zephyr/dts/x86/intel/elkhart_lake.dtsi:622 */
		gpio_3_vG: gpio@fd6b09b0 {
			compatible = "intel,gpio";       /* in zephyr/dts/x86/intel/elkhart_lake.dtsi:623 */
			reg = < 0xfd6b09b0 0x1000 >;     /* in zephyr/dts/x86/intel/elkhart_lake.dtsi:624 */
			interrupts = < 0xe 0xa100 0x3 >; /* in zephyr/dts/x86/intel/elkhart_lake.dtsi:625 */
			interrupt-parent = < &intc >;    /* in zephyr/dts/x86/intel/elkhart_lake.dtsi:626 */
			group-index = < 0x3 >;           /* in zephyr/dts/x86/intel/elkhart_lake.dtsi:628 */
			gpio-controller;                 /* in zephyr/dts/x86/intel/elkhart_lake.dtsi:629 */
			#gpio-cells = < 0x2 >;           /* in zephyr/dts/x86/intel/elkhart_lake.dtsi:630 */
			ngpios = < 0x4 >;                /* in zephyr/dts/x86/intel/elkhart_lake.dtsi:632 */
			pin-offset = < 0x31 >;           /* in zephyr/dts/x86/intel/elkhart_lake.dtsi:633 */
			status = "okay";                 /* in zephyr/dts/x86/intel/elkhart_lake.dtsi:635 */
		};

		/* node '/soc/gpio@fd6a0700' defined in zephyr/dts/x86/intel/elkhart_lake.dtsi:638 */
		gpio_4_c: gpio@fd6a0700 {
			compatible = "intel,gpio";       /* in zephyr/dts/x86/intel/elkhart_lake.dtsi:639 */
			reg = < 0xfd6a0700 0x1000 >;     /* in zephyr/dts/x86/intel/elkhart_lake.dtsi:640 */
			interrupts = < 0xe 0xa100 0x3 >; /* in zephyr/dts/x86/intel/elkhart_lake.dtsi:641 */
			interrupt-parent = < &intc >;    /* in zephyr/dts/x86/intel/elkhart_lake.dtsi:642 */
			group-index = < 0x0 >;           /* in zephyr/dts/x86/intel/elkhart_lake.dtsi:644 */
			gpio-controller;                 /* in zephyr/dts/x86/intel/elkhart_lake.dtsi:645 */
			#gpio-cells = < 0x2 >;           /* in zephyr/dts/x86/intel/elkhart_lake.dtsi:646 */
			ngpios = < 0x18 >;               /* in zephyr/dts/x86/intel/elkhart_lake.dtsi:648 */
			pin-offset = < 0x0 >;            /* in zephyr/dts/x86/intel/elkhart_lake.dtsi:649 */
			status = "okay";                 /* in zephyr/dts/x86/intel/elkhart_lake.dtsi:651 */
		};

		/* node '/soc/gpio@fd6a0880' defined in zephyr/dts/x86/intel/elkhart_lake.dtsi:654 */
		gpio_4_f: gpio@fd6a0880 {
			compatible = "intel,gpio";       /* in zephyr/dts/x86/intel/elkhart_lake.dtsi:655 */
			reg = < 0xfd6a0880 0x1000 >;     /* in zephyr/dts/x86/intel/elkhart_lake.dtsi:656 */
			interrupts = < 0xe 0xa100 0x3 >; /* in zephyr/dts/x86/intel/elkhart_lake.dtsi:657 */
			interrupt-parent = < &intc >;    /* in zephyr/dts/x86/intel/elkhart_lake.dtsi:658 */
			group-index = < 0x1 >;           /* in zephyr/dts/x86/intel/elkhart_lake.dtsi:660 */
			gpio-controller;                 /* in zephyr/dts/x86/intel/elkhart_lake.dtsi:661 */
			#gpio-cells = < 0x2 >;           /* in zephyr/dts/x86/intel/elkhart_lake.dtsi:662 */
			ngpios = < 0x18 >;               /* in zephyr/dts/x86/intel/elkhart_lake.dtsi:664 */
			pin-offset = < 0x18 >;           /* in zephyr/dts/x86/intel/elkhart_lake.dtsi:665 */
			status = "okay";                 /* in zephyr/dts/x86/intel/elkhart_lake.dtsi:667 */
		};

		/* node '/soc/gpio@fd6a0a70' defined in zephyr/dts/x86/intel/elkhart_lake.dtsi:670 */
		gpio_4_e: gpio@fd6a0a70 {
			compatible = "intel,gpio";       /* in zephyr/dts/x86/intel/elkhart_lake.dtsi:671 */
			reg = < 0xfd6a0a70 0x1000 >;     /* in zephyr/dts/x86/intel/elkhart_lake.dtsi:672 */
			interrupts = < 0xe 0xa100 0x3 >; /* in zephyr/dts/x86/intel/elkhart_lake.dtsi:673 */
			interrupt-parent = < &intc >;    /* in zephyr/dts/x86/intel/elkhart_lake.dtsi:674 */
			group-index = < 0x3 >;           /* in zephyr/dts/x86/intel/elkhart_lake.dtsi:676 */
			gpio-controller;                 /* in zephyr/dts/x86/intel/elkhart_lake.dtsi:677 */
			#gpio-cells = < 0x2 >;           /* in zephyr/dts/x86/intel/elkhart_lake.dtsi:678 */
			ngpios = < 0x18 >;               /* in zephyr/dts/x86/intel/elkhart_lake.dtsi:680 */
			pin-offset = < 0x39 >;           /* in zephyr/dts/x86/intel/elkhart_lake.dtsi:681 */
			status = "okay";                 /* in zephyr/dts/x86/intel/elkhart_lake.dtsi:683 */
		};

		/* node '/soc/gpio@fd690700' defined in zephyr/dts/x86/intel/elkhart_lake.dtsi:686 */
		gpio_5_r: gpio@fd690700 {
			compatible = "intel,gpio";       /* in zephyr/dts/x86/intel/elkhart_lake.dtsi:687 */
			reg = < 0xfd690700 0x1000 >;     /* in zephyr/dts/x86/intel/elkhart_lake.dtsi:688 */
			interrupts = < 0xe 0xa100 0x3 >; /* in zephyr/dts/x86/intel/elkhart_lake.dtsi:689 */
			interrupt-parent = < &intc >;    /* in zephyr/dts/x86/intel/elkhart_lake.dtsi:690 */
			group-index = < 0x0 >;           /* in zephyr/dts/x86/intel/elkhart_lake.dtsi:692 */
			gpio-controller;                 /* in zephyr/dts/x86/intel/elkhart_lake.dtsi:693 */
			#gpio-cells = < 0x2 >;           /* in zephyr/dts/x86/intel/elkhart_lake.dtsi:694 */
			ngpios = < 0x8 >;                /* in zephyr/dts/x86/intel/elkhart_lake.dtsi:696 */
			pin-offset = < 0x0 >;            /* in zephyr/dts/x86/intel/elkhart_lake.dtsi:697 */
			status = "okay";                 /* in zephyr/dts/x86/intel/elkhart_lake.dtsi:699 */
		};

		/* node '/soc/hpet@fed00000' defined in zephyr/dts/x86/intel/elkhart_lake.dtsi:702 */
		hpet: hpet@fed00000 {
			compatible = "intel,hpet";    /* in zephyr/dts/x86/intel/elkhart_lake.dtsi:703 */
			reg = < 0xfed00000 0x400 >;   /* in zephyr/dts/x86/intel/elkhart_lake.dtsi:704 */
			interrupts = < 0x2 0x0 0x4 >; /* in zephyr/dts/x86/intel/elkhart_lake.dtsi:705 */
			interrupt-parent = < &intc >; /* in zephyr/dts/x86/intel/elkhart_lake.dtsi:706 */
			status = "okay";              /* in zephyr/dts/x86/intel/elkhart_lake.dtsi:708 */
		};

		/* node '/soc/tco_wdt@400' defined in zephyr/dts/x86/intel/elkhart_lake.dtsi:711 */
		tco_wdt: tco_wdt@400 {
			compatible = "intel,tco-wdt"; /* in zephyr/dts/x86/intel/elkhart_lake.dtsi:712 */
			reg = < 0x400 0x20 >;         /* in zephyr/dts/x86/intel/elkhart_lake.dtsi:713 */
			status = "disabled";          /* in zephyr/dts/x86/intel/elkhart_lake.dtsi:715 */
		};

		/* node '/soc/mfd@70' defined in zephyr/dts/x86/intel/elkhart_lake.dtsi:718 */
		mfd: mfd@70 {
			compatible = "motorola,mc146818-mfd";          /* in zephyr/dts/x86/intel/elkhart_lake.dtsi:719 */
			reg = < 0x70 0x1 0x71 0x1 0x72 0x1 0x73 0x1 >; /* in zephyr/dts/x86/intel/elkhart_lake.dtsi:720 */
			status = "okay";                               /* in zephyr/dts/x86/intel/elkhart_lake.dtsi:737 */

			/* node '/soc/mfd@70/rtc' defined in zephyr/dts/x86/intel/elkhart_lake.dtsi:722 */
			rtc: counter: rtc {
				compatible = "motorola,mc146818"; /* in zephyr/dts/x86/intel/elkhart_lake.dtsi:723 */
				interrupts = < 0x8 0x100 0x3 >;   /* in zephyr/dts/x86/intel/elkhart_lake.dtsi:724 */
				interrupt-parent = < &intc >;     /* in zephyr/dts/x86/intel/elkhart_lake.dtsi:725 */
				alarms-count = < 0x1 >;           /* in zephyr/dts/x86/intel/elkhart_lake.dtsi:726 */
				status = "okay";                  /* in zephyr/dts/x86/intel/elkhart_lake.dtsi:728 */
			};

			/* node '/soc/mfd@70/bbram' defined in zephyr/dts/x86/intel/elkhart_lake.dtsi:731 */
			bbram: bbram {
				compatible = "motorola,mc146818-bbram"; /* in zephyr/dts/x86/intel/elkhart_lake.dtsi:732 */
				size = < 0xf1 >;                        /* in zephyr/dts/x86/intel/elkhart_lake.dtsi:733 */
				status = "okay";                        /* in zephyr/dts/x86/intel/elkhart_lake.dtsi:734 */
			};
		};
	};
};
